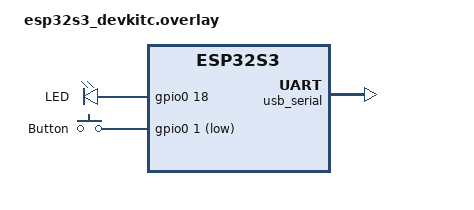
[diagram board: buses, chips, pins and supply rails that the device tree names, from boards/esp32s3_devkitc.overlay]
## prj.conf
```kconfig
CONFIG_SERIAL=y
CONFIG_CONSOLE=y
CONFIG_LOG=y
CONFIG_LOG_MODE_MINIMAL=y
CONFIG_UART_CONSOLE=y

CONFIG_SHELL=y
```

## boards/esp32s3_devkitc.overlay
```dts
/ {

    chosen {
        zephyr,console = &usb_serial;
        zephyr,shell-uart = &usb_serial;
    };


    leds {
        compatible = "gpio-leds";
        my_led0: led_0 {
            gpios = <&gpio0 18 GPIO_ACTIVE_HIGH>;
            label = "LED";
        };
    };

    buttons {
        compatible = "gpio-keys";
        my_button0: button_0 {
            gpios = <&gpio0 1 GPIO_ACTIVE_LOW>;
            label = "Button";
        };
    };

    aliases {
        led = &my_led0;
        button = &my_button0;
    };
};

&usb_serial {
    status = "okay";
};
```

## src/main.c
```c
#include <zephyr/kernel.h>
#include <zephyr/drivers/gpio.h>

#define LED_NODE DT_ALIAS(led)
#define BUTTON_NODE DT_ALIAS(button)

static const struct gpio_dt_spec led = GPIO_DT_SPEC_GET(LED_NODE, gpios);
static const struct gpio_dt_spec button = GPIO_DT_SPEC_GET(BUTTON_NODE, gpios);

int main() {

    if (!gpio_is_ready_dt(&led)) {
        while(1) {
            printf("Led not initialized");
        }
    }
    gpio_pin_configure_dt(&led, GPIO_OUTPUT_INACTIVE);

    if (!gpio_is_ready_dt(&button)) {
        while(1) {
            printf("Button not initialized");
        }
    }
    gpio_pin_configure_dt(&button, GPIO_INPUT);

    while (1) {
        int button_state = gpio_pin_get_dt(&button);
        gpio_pin_set_dt(&led, button_state);
        // printk("Button state: %d\n", button_state);
        k_msleep(10);

    }

    return 0;
}
```
